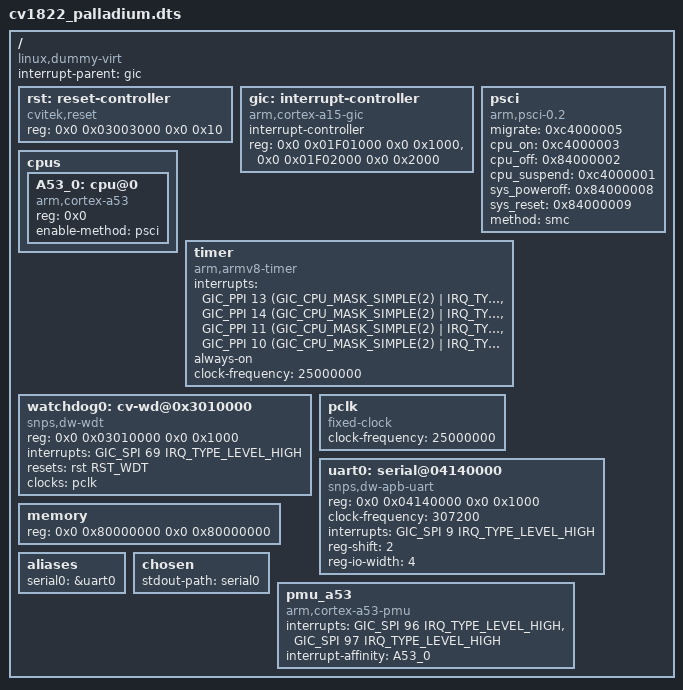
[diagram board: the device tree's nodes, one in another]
#include <dt-bindings/interrupt-controller/arm-gic.h>
#include <dt-bindings/gpio/gpio.h>
#include <dt-bindings/reset/cv1835-resets.h>
#include <dt-bindings/sound/cv1835-audio.h>

/dts-v1/;

/memreserve/	0x80000000 0x0000000000080000; // ATF BL31 + BL32

/ {
	compatible = "linux,dummy-virt";
	#size-cells = <0x2>;
	#address-cells = <0x2>;
	interrupt-parent = <&gic>;

	rst: reset-controller {
		#reset-cells = <1>;
		compatible = "cvitek,reset";
		reg = <0x0 0x03003000 0x0 0x10>;
	};

	gic: interrupt-controller {
		compatible = "arm,cortex-a15-gic";
		ranges;
		#size-cells = <0x2>;
		#address-cells = <0x2>;
		interrupt-controller;
		#interrupt-cells = <0x3>;
		reg = <0x0 0x01F01000 0x0 0x1000>,
		      <0x0 0x01F02000 0x0 0x2000>;
	};

	psci {
		migrate = <0xc4000005>;
		cpu_on = <0xc4000003>;
		cpu_off = <0x84000002>;
		cpu_suspend = <0xc4000001>;
		sys_poweroff = <0x84000008>;
		sys_reset = <0x84000009>;
		method = "smc";
		compatible = "arm,psci-0.2", "arm,psci";
	};

	cpus {
		#size-cells = <0x0>;
		#address-cells = <0x1>;

		A53_0: cpu@0 {
			reg = <0x0>;
			enable-method = "psci";
			compatible = "arm,cortex-a53";
			device_type = "cpu";
		};
	};

	timer {
		interrupts = <GIC_PPI 13 (GIC_CPU_MASK_SIMPLE(2) | IRQ_TYPE_LEVEL_LOW)>,
			<GIC_PPI 14 (GIC_CPU_MASK_SIMPLE(2) | IRQ_TYPE_LEVEL_LOW)>,
			<GIC_PPI 11 (GIC_CPU_MASK_SIMPLE(2) | IRQ_TYPE_LEVEL_LOW)>,
			<GIC_PPI 10 (GIC_CPU_MASK_SIMPLE(2) | IRQ_TYPE_LEVEL_LOW)>;
		always-on;
		clock-frequency = <25000000>;
		compatible = "arm,armv8-timer";
	};

	watchdog0: cv-wd@0x3010000 {
		compatible = "snps,dw-wdt";
		reg = <0x0 0x03010000 0x0 0x1000>;
		interrupts = <GIC_SPI 69 IRQ_TYPE_LEVEL_HIGH>;
		resets = <&rst RST_WDT>;
		clocks = <&pclk>;
	};

	pclk: pclk {
		#clock-cells = <0>;
		compatible = "fixed-clock";
		clock-frequency = <25000000>;
	};

	uart0: serial@04140000 {
		compatible = "snps,dw-apb-uart";
		reg = <0x0 0x04140000 0x0 0x1000>;
		clock-frequency = <307200>;
		interrupts = <GIC_SPI 9 IRQ_TYPE_LEVEL_HIGH>;
		reg-shift = <2>;
		reg-io-width = <4>;
	};

	memory {
		reg = <0x0 0x80000000 0x0 0x80000000>;
		device_type = "memory";
	};

	aliases {
		serial0 = &uart0;
	};

	chosen {
		stdout-path = "serial0"; // "serial0:115200n8", no arguments means no re-initialization
	};

	pmu_a53 {
		compatible = "arm,cortex-a53-pmu";
		interrupts = <GIC_SPI 96 IRQ_TYPE_LEVEL_HIGH>,
			     <GIC_SPI 97 IRQ_TYPE_LEVEL_HIGH>;
		interrupt-affinity = <&A53_0>;
	};

};

